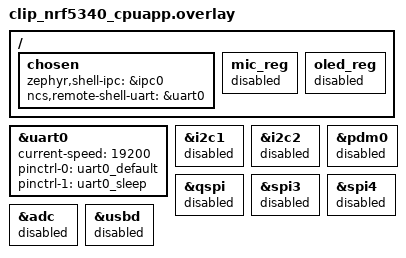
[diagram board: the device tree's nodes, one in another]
/*
 * Copyright (c) 2024 Seeed Studio
 *
 * SPDX-License-Identifier: LicenseRef-Nordic-5-Clause
 */

/ {
	chosen {
		zephyr,shell-ipc = &ipc0;
		ncs,remote-shell-uart = &uart0;
		/delete-property/ zephyr,console;
		/delete-property/ zephyr,shell-uart;
	};
};

&uart0 {
	status = "okay";
	current-speed = <19200>;
	pinctrl-0 = <&uart0_default>;
	pinctrl-1 = <&uart0_sleep>;
	pinctrl-names = "default", "sleep";
};

/* Disable power regulators */

/ {
	mic_reg {
		status = "disabled";
	};
	oled_reg {
		status = "disabled";
	};
};

/* Disable all unused peripherals */

&i2c1 {
	status = "disabled";
};

&i2c2 {
	status = "disabled";
};

&pdm0 {
	status = "disabled";
};

&qspi {
	status = "disabled";
};

&spi3 {
	status = "disabled";
};

&spi4 {
	status = "disabled";
};

&adc {
	status = "disabled";
};

&usbd {
	status = "disabled";
};
